AUTOSAR XML (schema 00047)
# (C) 2021 HYUNDAI AUTOEVER Corp.
# Confidential Proprietary Information. Distribution Limited.
# Do Not Copy Without Prior Permission
package /Svc_Dcm
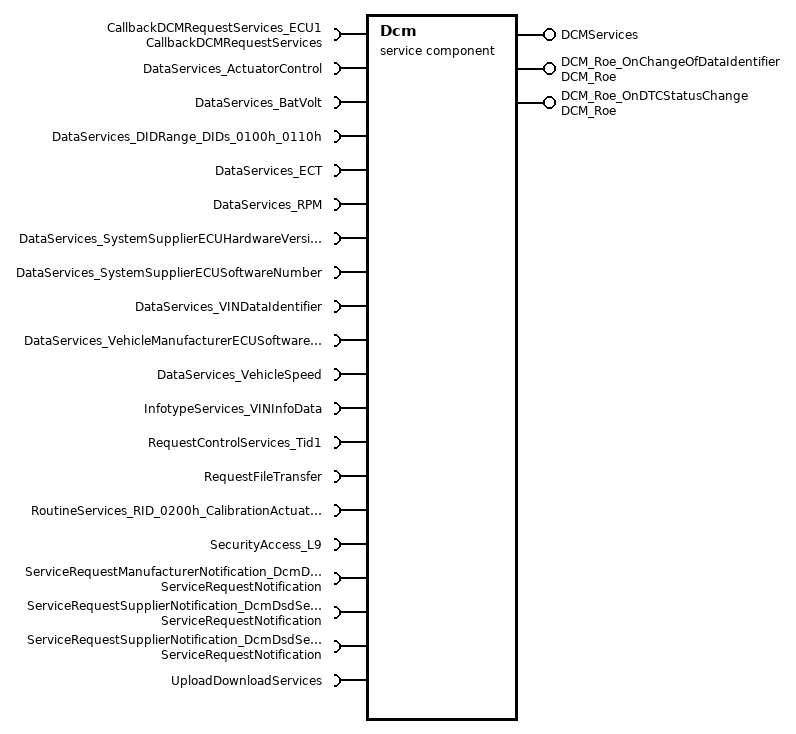
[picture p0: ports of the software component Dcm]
  service sw component type Dcm
    require port CallbackDCMRequestServices_ECU1: required-com-specs=[StartProtocol, StopProtocol], required-interface=CallbackDCMRequestServices
    provide port DCMServices: provided-interface=DCMServices
      provided-com-specs:
        operation=GetActiveProtocol, queue-length=1
        operation=GetSecurityLevel, queue-length=1
        operation=GetSesCtrlType, queue-length=1
        operation=ResetToDefaultSession, queue-length=1
        operation=SetActiveDiagnostic, queue-length=1
    provide port DCM_Roe_OnChangeOfDataIdentifier: server-com-spec{operation=TriggerOnEvent, queue-length=1}, provided-interface=DCM_Roe
    provide port DCM_Roe_OnDTCStatusChange: server-com-spec{operation=TriggerOnEvent, queue-length=1}, provided-interface=DCM_Roe
    19 x require port:
      DataServices_ActuatorControl: required-interface=DataServices_ActuatorControl
        required-com-specs:
          DataServices_ActuatorControl/ConditionCheckRead
          DataServices_ActuatorControl/ReadData
          DataServices_ActuatorControl/WriteData
          DataServices_ActuatorControl/FreezeCurrentState
          ResetToDefault
          DataServices_ActuatorControl/ReturnControlToECU
          DataServices_ActuatorControl/ShortTermAdjustment
      DataServices_BatVolt: required-com-specs=[DataServices_BatVolt/ConditionCheckRead, DataServices_BatVolt/ReadData, DataServices_BatVolt/WriteData], required-interface=DataServices_BatVolt
      DataServices_DIDRange_DIDs_0100h_0110h: required-com-specs=[IsDidAvailable, ReadDidData, ReadDidRangeDataLength, WriteDidData], required-interface=DataServices_DIDRange_DIDs_0100h_0110h
      DataServices_ECT: required-com-specs=[DataServices_ECT/ConditionCheckRead, DataServices_ECT/ReadData, DataServices_ECT/WriteData], required-interface=DataServices_ECT
      DataServices_RPM: required-interface=DataServices_RPM
        required-com-specs:
          DataServices_RPM/ConditionCheckRead
          DataServices_RPM/ReadData
          DataServices_RPM/WriteData
          DataServices_RPM/FreezeCurrentState
          DataServices_RPM/ReturnControlToECU
          DataServices_RPM/ShortTermAdjustment
      DataServices_SystemSupplierECUHardwareVersionNumber: required-interface=DataServices_SystemSupplierECUHardwareVersionNumber
        required-com-specs:
          DataServices_SystemSupplierECUHardwareVersionNumber/ConditionCheckRead
          DataServices_SystemSupplierECUHardwareVersionNumber/ReadData
      DataServices_SystemSupplierECUSoftwareNumber: required-interface=DataServices_SystemSupplierECUSoftwareNumber
        required-com-specs:
          DataServices_SystemSupplierECUSoftwareNumber/ConditionCheckRead
          DataServices_SystemSupplierECUSoftwareNumber/ReadData
      DataServices_VINDataIdentifier: required-interface=DataServices_VINDataIdentifier
        required-com-specs:
          DataServices_VINDataIdentifier/ConditionCheckRead
          DataServices_VINDataIdentifier/GetScalingInformation
          DataServices_VINDataIdentifier/ReadData
          DataServices_VINDataIdentifier/WriteData
      DataServices_VehicleManufacturerECUSoftwareVersionNumber: required-interface=DataServices_VehicleManufacturerECUSoftwareVersionNumber
        required-com-specs:
          DataServices_VehicleManufacturerECUSoftwareVersionNumber/ConditionCheckRead
          DataServices_VehicleManufacturerECUSoftwareVersionNumber/ReadData
      DataServices_VehicleSpeed: required-interface=DataServices_VehicleSpeed
        required-com-specs:
          DataServices_VehicleSpeed/ConditionCheckRead
          DataServices_VehicleSpeed/GetScalingInformation
          DataServices_VehicleSpeed/ReadData
      InfotypeServices_VINInfoData: client-com-spec=GetInfotypeValueData, required-interface=InfotypeServices_VINInfoData
      RequestControlServices_Tid1: client-com-spec=RequestControl, required-interface=RequestControlServices_Tid1
      RequestFileTransfer: required-interface=RequestFileTransfer
        required-com-specs:
          ProcessRequestAddFile
          ProcessRequestDeleteFile
          ProcessRequestReadDir
          ProcessRequestReadFile
          ProcessRequestReplaceFile
          ReadFileOrDir
          WriteFile
      RoutineServices_RID_0200h_CalibrationActuator: required-com-specs=[Stop, Start, RequestResults], required-interface=RoutineServices_RID_0200h_CalibrationActuator
      SecurityAccess_L9: required-com-specs=[CompareKey, GetSeed], required-interface=SecurityAccess_L9
      ServiceRequestManufacturerNotification_DcmDsdServiceRequestManufacturerNotification0: required-com-specs=[Confirmation, Indication], required-interface=ServiceRequestNotification
      ServiceRequestSupplierNotification_DcmDsdServiceRequestSupplierNotification0: required-com-specs=[Confirmation, Indication], required-interface=ServiceRequestNotification
      ServiceRequestSupplierNotification_DcmDsdServiceRequestSupplierNotification1: required-com-specs=[Confirmation, Indication], required-interface=ServiceRequestNotification
      UploadDownloadServices: required-interface=UploadDownloadServices
        required-com-specs:
          ProcessRequestDownload
          ProcessRequestUpload
          ProcessRequestTransferExit
          ProcessTransferDataRead
          ProcessTransferDataWrite
    behavior DcmInternalBehavior: handle-termination-and-restart=NO-SUPPORT, included-data-type-set=data-type=[Dcm_CertAuthorizationInfoType, Dcm_CertExpirationDateInfoType, Dcm_CertInfoType, Dcm_ConfirmationStatusType, Dcm_DataArrayTypeUint8_ActuatorControlType, Dcm_DataArrayTypeUint8_RPMType, Dcm_DataElement_ActuatorControlType, Dcm_DataElement_ActuatorControl_ArrayType, Dcm_DataElement_BatVoltType, Dcm_DataElement_BatVolt_ArrayType, Dcm_DataElement_ECTType, Dcm_DataElement_ECT_ArrayType, Dcm_DataElement_RPMType, Dcm_DataElement_RPM_ArrayType, Dcm_DataElement_SystemSupplierECUHardwareVersionNumberType, Dcm_DataElement_SystemSupplierECUHardwareVersionNumber_ArrayType, Dcm_DataElement_SystemSupplierECUSoftwareNumberType, Dcm_DataElement_SystemSupplierECUSoftwareNumber_ArrayType, Dcm_DataElement_VINDataIdentifierType, Dcm_DataElement_VINDataIdentifier_ArrayType, Dcm_DataElement_VehicleManufacturerECUSoftwareVersionNumberType, Dcm_DataElement_VehicleManufacturerECUSoftwareVersionNumber_ArrayType, Dcm_DataElement_VehicleSpeedType, Dcm_DataElement_VehicleSpeed_ArrayType, Dcm_DidSupportedType, Dcm_FileAndDirNameType, Dcm_IOOperationResponseType, Dcm_InfoTypeServicesArray_VINInfoDataType, Dcm_InputOutputControlParameterType, Dcm_KeyArray_L9Type, Dcm_NegativeResponseCodeType, Dcm_OpStatusType, Dcm_ProtocolType, Dcm_RangeArray_DIDs_0100h_0110hType, Dcm_RequestControlServicesInArray_Tid1Type, Dcm_RequestControlServicesOutArray_Tid1Type, Dcm_RequestDataArrayType, Dcm_RequestDataOut_RID_0200h_CalibrationActuator_RID_0200h_RequestOutSignalType, Dcm_RequestDataOut_RID_0200h_CalibrationActuator_RID_0200h_RequestOutSignal_PrimitiveType, Dcm_ResponseDataArrayType, Dcm_ScalingInfoArray_VINDataIdentifierType, Dcm_ScalingInfoArray_VehicleSpeedType, Dcm_SecLevelType, Dcm_SeedArray_L9Type, Dcm_SesCtrlType, Dcm_StartDataIn_RID_0200h_CalibrationActuator_RID_0200h_StartInSignalType, Dcm_StartDataIn_RID_0200h_CalibrationActuator_RID_0200h_StartInSignal_PrimitiveType, Dcm_StartDataOut_RID_0200h_CalibrationActuator_RID_0200h_StartOutSignalType, Dcm_StartDataOut_RID_0200h_CalibrationActuator_RID_0200h_StartOutSignal_PrimitiveType, Dcm_StopDataIn_RID_0200h_CalibrationActuator_RID_0200h_StopInSignalType, Dcm_StopDataIn_RID_0200h_CalibrationActuator_RID_0200h_StopInSignal_PrimitiveType, Dcm_StopDataOut_RID_0200h_CalibrationActuator_RID_0200h_StopOutSignalType, Dcm_StopDataOut_RID_0200h_CalibrationActuator_RID_0200h_StopOutSignal_PrimitiveType]
      7 x operation invoked event:
        IOE_DCM_Roe_OnChangeOfDataIdentifier_TriggerOnEvent: start-on-event=TriggerOnEvent, operation=DCM_Roe_OnChangeOfDataIdentifier.TriggerOnEvent
        IOE_DCM_Roe_OnDTCStatusChange_TriggerOnEvent: start-on-event=TriggerOnEvent, operation=DCM_Roe_OnDTCStatusChange.TriggerOnEvent
        OIE_DCMServices_GetActiveProtocol: start-on-event=GetActiveProtocol, operation=DCMServices.GetActiveProtocol
        OIE_DCMServices_GetSecurityLevel: start-on-event=GetSecurityLevel, operation=DCMServices.GetSecurityLevel
        OIE_DCMServices_GetSesCtrlType: start-on-event=GetSesCtrlType, operation=DCMServices.GetSesCtrlType
        OIE_DCMServices_ResetToDefaultSession: start-on-event=ResetToDefaultSession, operation=DCMServices.ResetToDefaultSession
        OIE_DCMServices_SetActiveDiagnostic: start-on-event=SetActiveDiagnostic, operation=DCMServices.SetActiveDiagnostic
      port-api-options:
        {enable-take-address=false, indirect-api=false, port-defined-argument-value{value=0x00, value-type=uint8}, port=DCM_Roe_OnDTCStatusChange}
        {enable-take-address=false, indirect-api=false, port-defined-argument-value{value=0x01, value-type=uint8}, port=DCM_Roe_OnChangeOfDataIdentifier}
      7 x runnable, all with can-be-invoked-concurrently=true:
        GetActiveProtocol: symbol=Dcm_GetActiveProtocol
        GetSecurityLevel: symbol=Dcm_GetSecurityLevel
        GetSesCtrlType: symbol=Dcm_GetSesCtrlType
        MainFunction: symbol=Dcm_MainFunction
          63 x sync call, all with timeout=0.0:
            SSCP_CallbackDCMRequestServices_ECU1_StartProtocol: operation=CallbackDCMRequestServices_ECU1.StartProtocol
            SSCP_CallbackDCMRequestServices_ECU1_StopProtocol: operation=CallbackDCMRequestServices_ECU1.StopProtocol
            SSCP_DataServices_ActuatorControl_ConditionCheckRead: operation=DataServices_ActuatorControl.ConditionCheckRead
            SSCP_DataServices_ActuatorControl_FreezeCurrentState: operation=DataServices_ActuatorControl.FreezeCurrentState
            SSCP_DataServices_ActuatorControl_ReadData: operation=DataServices_ActuatorControl.ReadData
            SSCP_DataServices_ActuatorControl_ResetToDefault: operation=DataServices_ActuatorControl.ResetToDefault
            SSCP_DataServices_ActuatorControl_ReturnControlToECU: operation=DataServices_ActuatorControl.ReturnControlToECU
            SSCP_DataServices_ActuatorControl_ShortTermAdjustment: operation=DataServices_ActuatorControl.ShortTermAdjustment
            SSCP_DataServices_ActuatorControl_WriteData: operation=DataServices_ActuatorControl.WriteData
            SSCP_DataServices_BatVolt_ConditionCheckRead: operation=DataServices_BatVolt.ConditionCheckRead
            SSCP_DataServices_BatVolt_ReadData: operation=DataServices_BatVolt.ReadData
            SSCP_DataServices_BatVolt_WriteData: operation=DataServices_BatVolt.WriteData
            SSCP_DataServices_DIDRange_DIDs_0100h_0110h_IsDidAvailable: operation=DataServices_DIDRange_DIDs_0100h_0110h.IsDidAvailable
            SSCP_DataServices_DIDRange_DIDs_0100h_0110h_ReadDidData: operation=DataServices_DIDRange_DIDs_0100h_0110h.ReadDidData
            SSCP_DataServices_DIDRange_DIDs_0100h_0110h_ReadDidRangeDataLength: operation=DataServices_DIDRange_DIDs_0100h_0110h.ReadDidRangeDataLength
            SSCP_DataServices_DIDRange_DIDs_0100h_0110h_WriteDidData: operation=DataServices_DIDRange_DIDs_0100h_0110h.WriteDidData
            SSCP_DataServices_ECT_ConditionCheckRead: operation=DataServices_ECT.ConditionCheckRead
            SSCP_DataServices_ECT_ReadData: operation=DataServices_ECT.ReadData
            SSCP_DataServices_ECT_WriteData: operation=DataServices_ECT.WriteData
            SSCP_DataServices_RPM_ConditionCheckRead: operation=DataServices_RPM.ConditionCheckRead
            SSCP_DataServices_RPM_FreezeCurrentState: operation=DataServices_RPM.FreezeCurrentState
            SSCP_DataServices_RPM_ReadData: operation=DataServices_RPM.ReadData
            SSCP_DataServices_RPM_ReturnControlToECU: operation=DataServices_RPM.ReturnControlToECU
            SSCP_DataServices_RPM_ShortTermAdjustment: operation=DataServices_RPM.ShortTermAdjustment
            SSCP_DataServices_RPM_WriteData: operation=DataServices_RPM.WriteData
            SSCP_DataServices_SystemSupplierECUHardwareVersionNumber_ConditionCheckRead: operation=DataServices_SystemSupplierECUHardwareVersionNumber.ConditionCheckRead
            SSCP_DataServices_SystemSupplierECUHardwareVersionNumber_ReadData: operation=DataServices_SystemSupplierECUHardwareVersionNumber.ReadData
            SSCP_DataServices_SystemSupplierECUSoftwareNumber_ConditionCheckRead: operation=DataServices_SystemSupplierECUSoftwareNumber.ConditionCheckRead
            SSCP_DataServices_SystemSupplierECUSoftwareNumber_ReadData: operation=DataServices_SystemSupplierECUSoftwareNumber.ReadData
            SSCP_DataServices_VINDataIdentifier_ConditionCheckRead: operation=DataServices_VINDataIdentifier.ConditionCheckRead
            SSCP_DataServices_VINDataIdentifier_GetScalingInformation: operation=DataServices_VINDataIdentifier.GetScalingInformation
            SSCP_DataServices_VINDataIdentifier_ReadData: operation=DataServices_VINDataIdentifier.ReadData
            SSCP_DataServices_VINDataIdentifier_WriteData: operation=DataServices_VINDataIdentifier.WriteData
            SSCP_DataServices_VehicleManufacturerECUSoftwareVersionNumber_ConditionCheckRead: operation=DataServices_VehicleManufacturerECUSoftwareVersionNumber.ConditionCheckRead
            SSCP_DataServices_VehicleManufacturerECUSoftwareVersionNumber_ReadData: operation=DataServices_VehicleManufacturerECUSoftwareVersionNumber.ReadData
            SSCP_DataServices_VehicleSpeed_ConditionCheckRead: operation=DataServices_VehicleSpeed.ConditionCheckRead
            SSCP_DataServices_VehicleSpeed_GetScalingInformation: operation=DataServices_VehicleSpeed.GetScalingInformation
            SSCP_DataServices_VehicleSpeed_ReadData: operation=DataServices_VehicleSpeed.ReadData
            SSCP_InfotypeServices_VINInfoData_GetInfotypeValueData: operation=InfotypeServices_VINInfoData.GetInfotypeValueData
            SSCP_RequestControlServices_Tid1_RequestControl: operation=RequestControlServices_Tid1.RequestControl
            SSCP_RequestFileTransfer_ProcessRequestAddFile: operation=RequestFileTransfer.ProcessRequestAddFile
            SSCP_RequestFileTransfer_ProcessRequestDeleteFile: operation=RequestFileTransfer.ProcessRequestDeleteFile
            SSCP_RequestFileTransfer_ProcessRequestReadDir: operation=RequestFileTransfer.ProcessRequestReadDir
            SSCP_RequestFileTransfer_ProcessRequestReadFile: operation=RequestFileTransfer.ProcessRequestReadFile
            SSCP_RequestFileTransfer_ProcessRequestReplaceFile: operation=RequestFileTransfer.ProcessRequestReplaceFile
            SSCP_RequestFileTransfer_ReadFileOrDir: operation=RequestFileTransfer.ReadFileOrDir
            SSCP_RequestFileTransfer_WriteFile: operation=RequestFileTransfer.WriteFile
            SSCP_RoutineServices_RID_0200h_CalibrationActuator_RequestResults: operation=RoutineServices_RID_0200h_CalibrationActuator.RequestResults
            SSCP_RoutineServices_RID_0200h_CalibrationActuator_Start: operation=RoutineServices_RID_0200h_CalibrationActuator.Start
            SSCP_RoutineServices_RID_0200h_CalibrationActuator_Stop: operation=RoutineServices_RID_0200h_CalibrationActuator.Stop
            SSCP_SecurityAccess_L9_CompareKey: operation=SecurityAccess_L9.CompareKey
            SSCP_SecurityAccess_L9_GetSeed: operation=SecurityAccess_L9.GetSeed
            SSCP_ServiceRequestManufacturerNotification_DcmDsdServiceRequestManufacturerNotification0_Confirmation: operation=ServiceRequestManufacturerNotification_DcmDsdServiceRequestManufacturerNotification0.Confirmation
            SSCP_ServiceRequestManufacturerNotification_DcmDsdServiceRequestManufacturerNotification0_Indication: operation=ServiceRequestManufacturerNotification_DcmDsdServiceRequestManufacturerNotification0.Indication
            SSCP_ServiceRequestSupplierNotification_DcmDsdServiceRequestSupplierNotification0_Confirmation: operation=ServiceRequestSupplierNotification_DcmDsdServiceRequestSupplierNotification0.Confirmation
            SSCP_ServiceRequestSupplierNotification_DcmDsdServiceRequestSupplierNotification0_Indication: operation=ServiceRequestSupplierNotification_DcmDsdServiceRequestSupplierNotification0.Indication
            SSCP_ServiceRequestSupplierNotification_DcmDsdServiceRequestSupplierNotification1_Confirmation: operation=ServiceRequestSupplierNotification_DcmDsdServiceRequestSupplierNotification1.Confirmation
            SSCP_ServiceRequestSupplierNotification_DcmDsdServiceRequestSupplierNotification1_Indication: operation=ServiceRequestSupplierNotification_DcmDsdServiceRequestSupplierNotification1.Indication
            SSCP_UploadDownloadServices_ProcessRequestDownload: operation=UploadDownloadServices.ProcessRequestDownload
            SSCP_UploadDownloadServices_ProcessRequestTransferExit: operation=UploadDownloadServices.ProcessRequestTransferExit
            SSCP_UploadDownloadServices_ProcessRequestUpload: operation=UploadDownloadServices.ProcessRequestUpload
            SSCP_UploadDownloadServices_ProcessTransferDataRead: operation=UploadDownloadServices.ProcessTransferDataRead
            SSCP_UploadDownloadServices_ProcessTransferDataWrite: operation=UploadDownloadServices.ProcessTransferDataWrite
        ResetToDefaultSession: symbol=Dcm_ResetToDefaultSession
        SetActiveDiagnostic: symbol=Dcm_SetActiveDiagnostic
        TriggerOnEvent: symbol=Dcm_Runnable_TriggerOnEvent
  swc implementation Dcm_SwcImplementation: programming-language=C, sw-version=1.0.0, swc-bsw-mapping=SwcBswMapping_Dcm, vendor-id=76, behavior=DcmInternalBehavior
    code-descriptors:
      code CodeDescriptor: artifact-descriptors=autosar-engineering-object={short-label=Dcm_LibObjects, category=SWLIB, domain=AUTOSAR_DCM}
    resource consumption ResourceConsumption
  swc bsw mapping SwcBswMapping_Dcm: bsw-behavior=BswInternalBehavior_Dcm, swc-bsw-runnable-mapping{bsw-entity=BswSE_Dcm_MainFunction, swc-runnable=MainFunction}, swc-behavior=DcmInternalBehavior
package /Svc_Dcm/ClientServerInterfaces
  20 x client server interface, all with is-service=true:
    CallbackDCMRequestServices
      operation StartProtocol: possible-error=[CallbackDCMRequestServices/E_NOT_OK, CallbackDCMRequestServices/E_OK, E_PROTOCOL_NOT_ALLOWED]
        arg ProtocolType: type=Dcm_ProtocolType, direction=IN
        arg TesterSourceAddress: type=uint16, direction=IN
        arg ConnectionId: type=uint16, direction=IN
      operation StopProtocol: possible-error=[CallbackDCMRequestServices/E_NOT_OK, CallbackDCMRequestServices/E_OK]
        arg ProtocolType: type=Dcm_ProtocolType, direction=IN
        arg TesterSourceAddress: type=uint16, direction=IN
        arg ConnectionId: type=uint16, direction=IN
      error E_NOT_OK: error-code=1
      error E_OK: error-code=0
      error E_PROTOCOL_NOT_ALLOWED: error-code=5
    DCMServices
      5 x operation:
        GetActiveProtocol: possible-error=DCMServices/E_OK
          arg ActiveProtocolType: type=Dcm_ProtocolType, direction=OUT
          arg ConnectionId: type=uint16, direction=OUT
          arg TesterSourceAddress: type=uint16, direction=OUT
        GetSecurityLevel: possible-error=[DCMServices/E_NOT_OK, DCMServices/E_OK]
          arg SecLevel: type=Dcm_SecLevelType, direction=OUT
        GetSesCtrlType: possible-error=[DCMServices/E_NOT_OK, DCMServices/E_OK]
          arg SesCtrlType: type=Dcm_SesCtrlType, direction=OUT
        ResetToDefaultSession: possible-error=[DCMServices/E_NOT_OK, DCMServices/E_OK]
        SetActiveDiagnostic: possible-error=DCMServices/E_OK
          arg ArgumentDataPrototype0: type=boolean, direction=IN
      error E_NOT_OK: error-code=1
      error E_OK: error-code=0
    DCM_Roe
      operation TriggerOnEvent: possible-error=[DCM_Roe/E_NOT_OK, DCM_Roe/E_OK]
      error E_NOT_OK: error-code=1
      error E_OK: error-code=0
    DataServices_ActuatorControl
      7 x operation, all with possible-error=[DataServices_ActuatorControl/E_NOT_OK, DataServices_ActuatorControl/E_OK]:
        ConditionCheckRead
          arg ErrorCode: type=Dcm_NegativeResponseCodeType, direction=OUT
        FreezeCurrentState
          arg ErrorCode: type=Dcm_NegativeResponseCodeType, direction=OUT
        ReadData
          arg Data: type=Dcm_DataElement_ActuatorControlType, direction=OUT
        ResetToDefault
          arg ErrorCode: type=Dcm_NegativeResponseCodeType, direction=OUT
        ReturnControlToECU
          arg ErrorCode: type=Dcm_NegativeResponseCodeType, direction=OUT
        ShortTermAdjustment
          arg ControlStateInfo: type=Dcm_DataArrayTypeUint8_ActuatorControlType, direction=IN
          arg ErrorCode: type=Dcm_NegativeResponseCodeType, direction=OUT
        WriteData
          arg Data: type=Dcm_DataElement_ActuatorControlType, direction=IN
          arg ErrorCode: type=Dcm_NegativeResponseCodeType, direction=OUT
      error DCM_E_PENDING: error-code=10
      error E_NOT_OK: error-code=1
      error E_OK: error-code=0
    DataServices_BatVolt
      operation ConditionCheckRead: possible-error=[DataServices_BatVolt/E_NOT_OK, DataServices_BatVolt/E_OK]
        arg ErrorCode: type=Dcm_NegativeResponseCodeType, direction=OUT
      operation ReadData: possible-error=[DataServices_BatVolt/E_NOT_OK, DataServices_BatVolt/E_OK]
        arg Data: type=Dcm_DataElement_BatVoltType, direction=OUT
      operation WriteData: possible-error=[DataServices_BatVolt/E_NOT_OK, DataServices_BatVolt/E_OK]
        arg Data: type=Dcm_DataElement_BatVoltType, direction=IN
        arg ErrorCode: type=Dcm_NegativeResponseCodeType, direction=OUT
      error DCM_E_PENDING: error-code=10
      error E_NOT_OK: error-code=1
      error E_OK: error-code=0
    DataServices_DIDRange_DIDs_0100h_0110h
      4 x operation:
        IsDidAvailable: possible-error=[DataServices_DIDRange_DIDs_0100h_0110h/DCM_E_PENDING, DataServices_DIDRange_DIDs_0100h_0110h/E_OK]
          arg DID: type=uint16, direction=IN
          arg OpStatus: type=Dcm_OpStatusType, direction=IN
          arg Supported: type=Dcm_DidSupportedType, direction=OUT
        ReadDidData: possible-error=[DataServices_DIDRange_DIDs_0100h_0110h/DCM_E_PENDING, DataServices_DIDRange_DIDs_0100h_0110h/E_NOT_OK, DataServices_DIDRange_DIDs_0100h_0110h/E_OK]
          5 x arg:
            DID: type=uint16, direction=IN
            Data: type=Dcm_RangeArray_DIDs_0100h_0110hType, direction=OUT
            OpStatus: type=Dcm_OpStatusType, direction=IN
            DataLength: type=uint16, direction=OUT
            ErrorCode: type=Dcm_NegativeResponseCodeType, direction=OUT
        ReadDidRangeDataLength: possible-error=[DataServices_DIDRange_DIDs_0100h_0110h/DCM_E_PENDING, DataServices_DIDRange_DIDs_0100h_0110h/E_NOT_OK, DataServices_DIDRange_DIDs_0100h_0110h/E_OK]
          arg DID: type=uint16, direction=IN
          arg OpStatus: type=Dcm_OpStatusType, direction=IN
          arg DataLength: type=uint16, direction=OUT
        WriteDidData: possible-error=[DataServices_DIDRange_DIDs_0100h_0110h/DCM_E_PENDING, DataServices_DIDRange_DIDs_0100h_0110h/E_NOT_OK, DataServices_DIDRange_DIDs_0100h_0110h/E_OK]
          5 x arg:
            DID: type=uint16, direction=IN
            Data: type=Dcm_RangeArray_DIDs_0100h_0110hType, direction=IN
            OpStatus: type=Dcm_OpStatusType, direction=IN
            DataLength: type=uint16, direction=IN
            ErrorCode: type=Dcm_NegativeResponseCodeType, direction=OUT
      error DCM_E_PENDING: error-code=10
      error E_NOT_OK: error-code=1
      error E_OK: error-code=0
    DataServices_ECT
      operation ConditionCheckRead: possible-error=[DataServices_ECT/E_NOT_OK, DataServices_ECT/E_OK]
        arg ErrorCode: type=Dcm_NegativeResponseCodeType, direction=OUT
      operation ReadData: possible-error=[DataServices_ECT/E_NOT_OK, DataServices_ECT/E_OK]
        arg Data: type=Dcm_DataElement_ECTType, direction=OUT
      operation WriteData: possible-error=[DataServices_ECT/E_NOT_OK, DataServices_ECT/E_OK]
        arg Data: type=Dcm_DataElement_ECTType, direction=IN
        arg ErrorCode: type=Dcm_NegativeResponseCodeType, direction=OUT
      error DCM_E_PENDING: error-code=10
      error E_NOT_OK: error-code=1
      error E_OK: error-code=0
    DataServices_RPM
      6 x operation, all with possible-error=[DataServices_RPM/E_NOT_OK, DataServices_RPM/E_OK]:
        ConditionCheckRead
          arg ErrorCode: type=Dcm_NegativeResponseCodeType, direction=OUT
        FreezeCurrentState
          arg ErrorCode: type=Dcm_NegativeResponseCodeType, direction=OUT
        ReadData
          arg Data: type=Dcm_DataElement_RPMType, direction=OUT
        ReturnControlToECU
          arg ErrorCode: type=Dcm_NegativeResponseCodeType, direction=OUT
        ShortTermAdjustment
          arg ControlStateInfo: type=Dcm_DataArrayTypeUint8_RPMType, direction=IN
          arg ErrorCode: type=Dcm_NegativeResponseCodeType, direction=OUT
        WriteData
          arg Data: type=Dcm_DataElement_RPMType, direction=IN
          arg ErrorCode: type=Dcm_NegativeResponseCodeType, direction=OUT
      error DCM_E_PENDING: error-code=10
      error E_NOT_OK: error-code=1
      error E_OK: error-code=0
    DataServices_SystemSupplierECUHardwareVersionNumber
      operation ConditionCheckRead: possible-error=[DataServices_SystemSupplierECUHardwareVersionNumber/E_NOT_OK, DataServices_SystemSupplierECUHardwareVersionNumber/E_OK]
        arg ErrorCode: type=Dcm_NegativeResponseCodeType, direction=OUT
      operation ReadData: possible-error=[DataServices_SystemSupplierECUHardwareVersionNumber/E_NOT_OK, DataServices_SystemSupplierECUHardwareVersionNumber/E_OK]
        arg Data: type=Dcm_DataElement_SystemSupplierECUHardwareVersionNumberType, direction=OUT
      error DCM_E_PENDING: error-code=10
      error E_NOT_OK: error-code=1
      error E_OK: error-code=0
    DataServices_SystemSupplierECUSoftwareNumber
      operation ConditionCheckRead: possible-error=[DataServices_SystemSupplierECUSoftwareNumber/E_NOT_OK, DataServices_SystemSupplierECUSoftwareNumber/E_OK]
        arg ErrorCode: type=Dcm_NegativeResponseCodeType, direction=OUT
      operation ReadData: possible-error=[DataServices_SystemSupplierECUSoftwareNumber/E_NOT_OK, DataServices_SystemSupplierECUSoftwareNumber/E_OK]
        arg Data: type=Dcm_DataElement_SystemSupplierECUSoftwareNumberType, direction=OUT
      error DCM_E_PENDING: error-code=10
      error E_NOT_OK: error-code=1
      error E_OK: error-code=0
    DataServices_VINDataIdentifier
      4 x operation, all with possible-error=[DataServices_VINDataIdentifier/E_NOT_OK, DataServices_VINDataIdentifier/E_OK]:
        ConditionCheckRead
          arg ErrorCode: type=Dcm_NegativeResponseCodeType, direction=OUT
        GetScalingInformation
          arg ScalingInfo: type=Dcm_ScalingInfoArray_VINDataIdentifierType, direction=OUT
          arg ErrorCode: type=Dcm_NegativeResponseCodeType, direction=OUT
        ReadData
          arg Data: type=Dcm_DataElement_VINDataIdentifierType, direction=OUT
        WriteData
          arg Data: type=Dcm_DataElement_VINDataIdentifierType, direction=IN
          arg ErrorCode: type=Dcm_NegativeResponseCodeType, direction=OUT
      error DCM_E_PENDING: error-code=10
      error E_NOT_OK: error-code=1
      error E_OK: error-code=0
    DataServices_VehicleManufacturerECUSoftwareVersionNumber
      operation ConditionCheckRead: possible-error=[DataServices_VehicleManufacturerECUSoftwareVersionNumber/E_NOT_OK, DataServices_VehicleManufacturerECUSoftwareVersionNumber/E_OK]
        arg ErrorCode: type=Dcm_NegativeResponseCodeType, direction=OUT
      operation ReadData: possible-error=[DataServices_VehicleManufacturerECUSoftwareVersionNumber/E_NOT_OK, DataServices_VehicleManufacturerECUSoftwareVersionNumber/E_OK]
        arg Data: type=Dcm_DataElement_VehicleManufacturerECUSoftwareVersionNumberType, direction=OUT
      error DCM_E_PENDING: error-code=10
      error E_NOT_OK: error-code=1
      error E_OK: error-code=0
    DataServices_VehicleSpeed
      operation ConditionCheckRead: possible-error=[DataServices_VehicleSpeed/E_NOT_OK, DataServices_VehicleSpeed/E_OK]
        arg ErrorCode: type=Dcm_NegativeResponseCodeType, direction=OUT
      operation GetScalingInformation: possible-error=[DataServices_VehicleSpeed/E_NOT_OK, DataServices_VehicleSpeed/E_OK]
        arg ScalingInfo: type=Dcm_ScalingInfoArray_VehicleSpeedType, direction=OUT
        arg ErrorCode: type=Dcm_NegativeResponseCodeType, direction=OUT
      operation ReadData: possible-error=[DataServices_VehicleSpeed/E_NOT_OK, DataServices_VehicleSpeed/E_OK]
        arg Data: type=Dcm_DataElement_VehicleSpeedType, direction=OUT
      error DCM_E_PENDING: error-code=10
      error E_NOT_OK: error-code=1
      error E_OK: error-code=0
    InfotypeServices_VINInfoData
      operation GetInfotypeValueData: possible-error=[InfotypeServices_VINInfoData/DCM_E_PENDING, InfotypeServices_VINInfoData/E_NOT_OK, InfotypeServices_VINInfoData/E_OK]
        arg OpStatus: type=Dcm_OpStatusType, direction=IN
        arg DataValueBuffer: type=Dcm_InfoTypeServicesArray_VINInfoDataType, direction=OUT
        arg DataValueBufferSize: type=uint8, direction=INOUT
      error DCM_E_PENDING: error-code=10
      error E_NOT_OK: error-code=1
      error E_OK: error-code=0
    RequestControlServices_Tid1
      operation RequestControl: possible-error=[RequestControlServices_Tid1/E_NOT_OK, RequestControlServices_Tid1/E_OK]
        arg OutBuffer: type=Dcm_RequestControlServicesOutArray_Tid1Type, direction=OUT
        arg InBuffer: type=Dcm_RequestControlServicesInArray_Tid1Type, direction=IN
      error E_NOT_OK: error-code=1
      error E_OK: error-code=0
    RequestFileTransfer
      7 x operation, all with possible-error=[RequestFileTransfer/DCM_E_FORCE_RCRRP, RequestFileTransfer/DCM_E_PENDING, RequestFileTransfer/E_NOT_OK, RequestFileTransfer/E_OK]:
        ProcessRequestAddFile
          8 x arg:
            OpStatus: type=Dcm_OpStatusType, direction=IN
            filePathAndNameLength: type=uint16, direction=IN
            filePathAndName: type=Dcm_FileAndDirNameType, direction=IN
            dataFormatIdentifier: type=uint8, direction=IN
            fileSizeUncompressed: type=uint64, direction=IN
            fileSizeCompressed: type=uint64, direction=IN
            maxNumberOfBlockLength: type=uint64, direction=OUT
            ErrorCode: type=Dcm_NegativeResponseCodeType, direction=OUT
        ProcessRequestDeleteFile
          4 x arg:
            OpStatus: type=Dcm_OpStatusType, direction=IN
            filePathAndNameLength: type=uint16, direction=IN
            filePathAndName: type=Dcm_FileAndDirNameType, direction=IN
            ErrorCode: type=Dcm_NegativeResponseCodeType, direction=OUT
        ProcessRequestReadDir
          6 x arg:
            OpStatus: type=Dcm_OpStatusType, direction=IN
            filePathAndNameLength: type=uint16, direction=IN
            filePathAndName: type=Dcm_FileAndDirNameType, direction=IN
            dirInfoLength: type=uint64, direction=OUT
            maxNumberOfBlockLength: type=uint64, direction=OUT
            ErrorCode: type=Dcm_NegativeResponseCodeType, direction=OUT
        ProcessRequestReadFile
          8 x arg:
            OpStatus: type=Dcm_OpStatusType, direction=IN
            filePathAndNameLength: type=uint16, direction=IN
            filePathAndName: type=Dcm_FileAndDirNameType, direction=IN
            dataFormatIdentifier: type=uint8, direction=IN
            fileSizeUncompressed: type=uint64, direction=OUT
            fileSizeCompressed: type=uint64, direction=OUT
            maxNumberOfBlockLength: type=uint64, direction=OUT
            ErrorCode: type=Dcm_NegativeResponseCodeType, direction=OUT
        ProcessRequestReplaceFile
          8 x arg:
            OpStatus: type=Dcm_OpStatusType, direction=IN
            filePathAndNameLength: type=uint16, direction=IN
            filePathAndName: type=Dcm_FileAndDirNameType, direction=IN
            dataFormatIdentifier: type=uint8, direction=IN
            fileSizeUncompressed: type=uint64, direction=IN
            fileSizeCompressed: type=uint64, direction=IN
            maxNumberOfBlockLength: type=uint64, direction=OUT
            ErrorCode: type=Dcm_NegativeResponseCodeType, direction=OUT
        ReadFileOrDir
          4 x arg:
            OpStatus: type=Dcm_OpStatusType, direction=IN
            DataLength: type=uint64, direction=INOUT
            Data: type=Dcm_ResponseDataArrayType, direction=OUT
            ErrorCode: type=Dcm_NegativeResponseCodeType, direction=OUT
        WriteFile
          4 x arg:
            OpStatus: type=Dcm_OpStatusType, direction=IN
            DataLength: type=uint64, direction=IN
            Data: type=Dcm_ResponseDataArrayType, direction=IN
            ErrorCode: type=Dcm_NegativeResponseCodeType, direction=OUT
      4 x error:
        DCM_E_FORCE_RCRRP: error-code=12
        DCM_E_PENDING: error-code=10
        E_NOT_OK: error-code=1
        E_OK: error-code=0
    RoutineServices_RID_0200h_CalibrationActuator
      operation RequestResults: possible-error=[RoutineServices_RID_0200h_CalibrationActuator/DCM_E_FORCE_RCRRP, RoutineServices_RID_0200h_CalibrationActuator/DCM_E_PENDING, RoutineServices_RID_0200h_CalibrationActuator/E_NOT_OK, RoutineServices_RID_0200h_CalibrationActuator/E_OK]
        arg OpStatus: type=Dcm_OpStatusType, direction=IN
        arg DataOut_RID_0200h_RequestOutSignal: type=Dcm_RequestDataOut_RID_0200h_CalibrationActuator_RID_0200h_RequestOutSignalType, direction=OUT
        arg ErrorCode: type=Dcm_NegativeResponseCodeType, direction=OUT
      operation Start: possible-error=[RoutineServices_RID_0200h_CalibrationActuator/DCM_E_FORCE_RCRRP, RoutineServices_RID_0200h_CalibrationActuator/DCM_E_PENDING, RoutineServices_RID_0200h_CalibrationActuator/E_NOT_OK, RoutineServices_RID_0200h_CalibrationActuator/E_OK]
        4 x arg:
          DataIn_RID_0200h_StartInSignal: type=Dcm_StartDataIn_RID_0200h_CalibrationActuator_RID_0200h_StartInSignalType, direction=IN
          OpStatus: type=Dcm_OpStatusType, direction=IN
          DataOut_RID_0200h_StartOutSignal: type=Dcm_StartDataOut_RID_0200h_CalibrationActuator_RID_0200h_StartOutSignalType, direction=OUT
          ErrorCode: type=Dcm_NegativeResponseCodeType, direction=OUT
      operation Stop: possible-error=[RoutineServices_RID_0200h_CalibrationActuator/DCM_E_FORCE_RCRRP, RoutineServices_RID_0200h_CalibrationActuator/DCM_E_PENDING, RoutineServices_RID_0200h_CalibrationActuator/E_NOT_OK, RoutineServices_RID_0200h_CalibrationActuator/E_OK]
        4 x arg:
          DataIn_RID_0200h_StopInSignal: type=Dcm_StopDataIn_RID_0200h_CalibrationActuator_RID_0200h_StopInSignalType, direction=IN
          OpStatus: type=Dcm_OpStatusType, direction=IN
          DataOut_RID_0200h_StopOutSignal: type=Dcm_StopDataOut_RID_0200h_CalibrationActuator_RID_0200h_StopOutSignalType, direction=OUT
          ErrorCode: type=Dcm_NegativeResponseCodeType, direction=OUT
      4 x error:
        DCM_E_FORCE_RCRRP: error-code=12
        DCM_E_PENDING: error-code=10
        E_NOT_OK: error-code=1
        E_OK: error-code=0
    SecurityAccess_L9
      operation CompareKey: possible-error=[DCM_E_COMPARE_KEY_FAILED, SecurityAccess_L9/DCM_E_PENDING, SecurityAccess_L9/E_NOT_OK, SecurityAccess_L9/E_OK]
        arg Key: type=Dcm_KeyArray_L9Type, direction=IN
        arg OpStatus: type=Dcm_OpStatusType, direction=IN
        arg ErrorCode: type=Dcm_NegativeResponseCodeType, direction=OUT
      operation GetSeed: possible-error=[SecurityAccess_L9/DCM_E_PENDING, SecurityAccess_L9/E_NOT_OK, SecurityAccess_L9/E_OK]
        arg OpStatus: type=Dcm_OpStatusType, direction=IN
        arg Seed: type=Dcm_SeedArray_L9Type, direction=OUT
        arg ErrorCode: type=Dcm_NegativeResponseCodeType, direction=OUT
      4 x error:
        DCM_E_COMPARE_KEY_FAILED: error-code=11
        DCM_E_PENDING: error-code=10
        E_NOT_OK: error-code=1
        E_OK: error-code=0
    ServiceRequestNotification
      operation Confirmation: possible-error=[ServiceRequestNotification/E_NOT_OK, ServiceRequestNotification/E_OK]
        6 x arg, all with direction=IN:
          SID: type=uint8
          ReqType: type=uint8
          ConnectionId: type=uint16
          ConfirmationStatus: type=Dcm_ConfirmationStatusType
          ProtocolType: type=Dcm_ProtocolType
          TesterSourceAddress: type=uint16
      operation Indication: possible-error=[ServiceRequestNotification/E_NOT_OK, ServiceRequestNotification/E_OK, E_REQUEST_NOT_ACCEPTED]
        8 x arg:
          SID: type=uint8, direction=IN
          RequestData: type=Dcm_RequestDataArrayType, direction=IN
          DataSize: type=uint16, direction=IN
          ReqType: type=uint8, direction=IN
          ConnectionId: type=uint16, direction=IN
          ErrorCode: type=Dcm_NegativeResponseCodeType, direction=OUT
          ProtocolType: type=Dcm_ProtocolType, direction=IN
          TesterSourceAddress: type=uint16, direction=IN
      error E_NOT_OK: error-code=1
      error E_OK: error-code=0
      error E_REQUEST_NOT_ACCEPTED: error-code=8
    UploadDownloadServices
      5 x operation:
        ProcessRequestDownload: possible-error=[UploadDownloadServices/DCM_E_PENDING, UploadDownloadServices/E_NOT_OK, UploadDownloadServices/E_OK]
          7 x arg:
            OpStatus: type=Dcm_OpStatusType, direction=IN
            DataFormatIdentifier: type=uint8, direction=IN
            MemoryIdentifier: type=uint8, direction=IN
            MemoryAddress: type=uint32, direction=IN
            MemorySize: type=uint32, direction=IN
            BlockLength: type=uint32, direction=INOUT
            ErrorCode: type=Dcm_NegativeResponseCodeType, direction=OUT
        ProcessRequestTransferExit: possible-error=[UploadDownloadServices/DCM_E_PENDING, UploadDownloadServices/E_NOT_OK, UploadDownloadServices/E_OK]
          arg OpStatus: type=Dcm_OpStatusType, direction=IN
          arg ErrorCode: type=Dcm_NegativeResponseCodeType, direction=OUT
        ProcessRequestUpload: possible-error=[UploadDownloadServices/DCM_E_PENDING, UploadDownloadServices/E_NOT_OK, UploadDownloadServices/E_OK]
          7 x arg:
            OpStatus: type=Dcm_OpStatusType, direction=IN
            DataFormatIdentifier: type=uint8, direction=IN
            MemoryIdentifier: type=uint8, direction=IN
            MemoryAddress: type=uint32, direction=IN
            MemorySize: type=uint32, direction=IN
            BlockLength: type=uint32, direction=INOUT
            ErrorCode: type=Dcm_NegativeResponseCodeType, direction=OUT
        ProcessTransferDataRead: possible-error=[UploadDownloadServices/DCM_E_FORCE_RCRRP, UploadDownloadServices/DCM_E_PENDING, UploadDownloadServices/E_NOT_OK, UploadDownloadServices/E_OK]
          6 x arg:
            OpStatus: type=Dcm_OpStatusType, direction=IN
            MemoryIdentifier: type=uint8, direction=IN
            MemoryAddress: type=uint32, direction=IN
            MemorySize: type=uint32, direction=IN
            MemoryData: type=Dcm_RequestDataArrayType, direction=OUT
            ErrorCode: type=Dcm_NegativeResponseCodeType, direction=OUT
        ProcessTransferDataWrite: possible-error=[UploadDownloadServices/DCM_E_FORCE_RCRRP, UploadDownloadServices/DCM_E_PENDING, UploadDownloadServices/E_NOT_OK, UploadDownloadServices/E_OK]
          6 x arg:
            OpStatus: type=Dcm_OpStatusType, direction=IN
            MemoryIdentifier: type=uint8, direction=IN
            MemoryAddress: type=uint32, direction=IN
            MemorySize: type=uint32, direction=IN
            MemoryData: type=Dcm_RequestDataArrayType, direction=IN
            ErrorCode: type=Dcm_NegativeResponseCodeType, direction=OUT
      4 x error:
        DCM_E_FORCE_RCRRP: error-code=12
        DCM_E_PENDING: error-code=10
        E_NOT_OK: error-code=1
        E_OK: error-code=0
package /Svc_Dcm/ImplementationDataTypes
  53 x impl type:
    Dcm_CertAuthorizationInfoType: category=ARRAY
      element authorization: array-size=4, array-size-semantics=FIXED-SIZE, implementation-data-type=uint8
    Dcm_CertExpirationDateInfoType: category=ARRAY
      element expirationDate: array-size=3, array-size-semantics=FIXED-SIZE, implementation-data-type=uint8
    Dcm_CertInfoType: category=STRUCTURE
      element authorization: implementation-data-type=Dcm_CertAuthorizationInfoType
      element expirationDate: implementation-data-type=Dcm_CertExpirationDateInfoType
    Dcm_ConfirmationStatusType: compu {0=DCM_RES_POS_OK, 1=DCM_RES_POS_NOT_OK, 2=DCM_RES_NEG_OK, 3=DCM_RES_NEG_NOT_OK}, range raw 0..3, implementation-data-type=uint8
    Dcm_DataArrayTypeUint8_ActuatorControlType: category=ARRAY
      element DataArrayUint8_ActuatorControl: array-size=1, array-size-semantics=FIXED-SIZE, implementation-data-type=uint8
    Dcm_DataArrayTypeUint8_RPMType: category=ARRAY
      element DataArrayUint8_RPM: array-size=2, array-size-semantics=FIXED-SIZE, implementation-data-type=uint8
    Dcm_DataElement_ActuatorControlType: implementation-data-type=Dcm_DataElement_ActuatorControl_ArrayType
    Dcm_DataElement_ActuatorControl_ArrayType: category=ARRAY
      element DataElement_ActuatorControl_Array: array-size=1, array-size-semantics=FIXED-SIZE, implementation-data-type=uint8
    Dcm_DataElement_BatVoltType: implementation-data-type=Dcm_DataElement_BatVolt_ArrayType
    Dcm_DataElement_BatVolt_ArrayType: category=ARRAY
      element DataElement_BatVolt_Array: array-size=1, array-size-semantics=FIXED-SIZE, implementation-data-type=uint8
    Dcm_DataElement_ECTType: implementation-data-type=Dcm_DataElement_ECT_ArrayType
    Dcm_DataElement_ECT_ArrayType: category=ARRAY
      element DataElement_ECT_Array: array-size=1, array-size-semantics=FIXED-SIZE, implementation-data-type=uint8
    Dcm_DataElement_RPMType: implementation-data-type=Dcm_DataElement_RPM_ArrayType
    Dcm_DataElement_RPM_ArrayType: category=ARRAY
      element DataElement_RPM_Array: array-size=2, array-size-semantics=FIXED-SIZE, implementation-data-type=uint8
    Dcm_DataElement_SystemSupplierECUHardwareVersionNumberType: implementation-data-type=Dcm_DataElement_SystemSupplierECUHardwareVersionNumber_ArrayType
    Dcm_DataElement_SystemSupplierECUHardwareVersionNumber_ArrayType: category=ARRAY
      element DataElement_SystemSupplierECUHardwareVersionNumber_Array: array-size=4, array-size-semantics=FIXED-SIZE, implementation-data-type=uint8
    Dcm_DataElement_SystemSupplierECUSoftwareNumberType: implementation-data-type=Dcm_DataElement_SystemSupplierECUSoftwareNumber_ArrayType
    Dcm_DataElement_SystemSupplierECUSoftwareNumber_ArrayType: category=ARRAY
      element DataElement_SystemSupplierECUSoftwareNumber_Array: array-size=4, array-size-semantics=FIXED-SIZE, implementation-data-type=uint8
    Dcm_DataElement_VINDataIdentifierType: implementation-data-type=Dcm_DataElement_VINDataIdentifier_ArrayType
    Dcm_DataElement_VINDataIdentifier_ArrayType: category=ARRAY
      element DataElement_VINDataIdentifier_Array: array-size=17, array-size-semantics=FIXED-SIZE, implementation-data-type=uint8
    Dcm_DataElement_VehicleManufacturerECUSoftwareVersionNumberType: implementation-data-type=Dcm_DataElement_VehicleManufacturerECUSoftwareVersionNumber_ArrayType
    Dcm_DataElement_VehicleManufacturerECUSoftwareVersionNumber_ArrayType: category=ARRAY
      element DataElement_VehicleManufacturerECUSoftwareVersionNumber_Array: array-size=17, array-size-semantics=FIXED-SIZE, implementation-data-type=uint8
    Dcm_DataElement_VehicleSpeedType: implementation-data-type=Dcm_DataElement_VehicleSpeed_ArrayType
    Dcm_DataElement_VehicleSpeed_ArrayType: category=ARRAY
      element DataElement_VehicleSpeed_Array: array-size=1, array-size-semantics=FIXED-SIZE, implementation-data-type=uint8
    Dcm_DidSupportedType: compu {0x00=DCM_DID_SUPPORTED, 0x01=DCM_DID_NOT_SUPPORTED}, range raw 0x00..0x01, implementation-data-type=uint8
    Dcm_FileAndDirNameType: category=ARRAY
      element FileAndDirName: array-size=4, array-size-semantics=FIXED-SIZE, implementation-data-type=uint8
    Dcm_IOOperationResponseType: compu {0x00=DCM_POSITIVE_RESPONSE, 0x10=DCM_GENERAL_REJECT, 0x21=DCM_BUSY_REPEAT_REQUEST, 0x22=DCM_CONDITIONS_NOT_CORRECT, 0x26=DCM_FAILURE_PREVENTS_EXECUTION, 0x31=DCM_REQUEST_OUT_OF_RANGE, 0x78=DCM_RESPONSE_PENDING}, range raw 0x00..0x78, implementation-data-type=uint8
    Dcm_InfoTypeServicesArray_VINInfoDataType: category=ARRAY
      element InfoServicesArray_VINInfoData: array-size=17, array-size-semantics=FIXED-SIZE, implementation-data-type=uint8
    Dcm_InputOutputControlParameterType: compu {0=DCM_RETURN_CONTROL_TO_ECU, 1=DCM_RESET_TO_DEFAULT, 2=DCM_FREEZE_CURRENT_STATE, 3=DCM_SHORT_TERM_ADJUSTMENT, 255=DCM_IDLE}, range raw 0..255, implementation-data-type=uint8
    Dcm_KeyArray_L9Type: category=ARRAY
      element KeyArray_L9: array-size=8, array-size-semantics=FIXED-SIZE, implementation-data-type=uint8
    Dcm_NegativeResponseCodeType:
      compu {0x00=DCM_POS_RESP, 0x10=DCM_E_GENERALREJECT, 0x11=DCM_E_SERVICENOTSUPPORTED, 0x12=DCM_E_SUBFUNCTIONNOTSUPPORTED, 0x13=DCM_E_INCORRECTMESSAGELENGTHORINVALIDFORMAT, 0x14=DCM_E_RESPONSETOOLONG, 0x21=DCM_E_BUSYREPEATREQUEST, 0x22=DCM_E_CONDITIONSNOTCORRECT, 0x24=DCM_E_REQUESTSEQUENCEERROR, 0x25=DCM_E_NORESPONSEFROMSUBNETCOMPONENT, 0x26=DCM_E_FAILUREPREVENTSEXECUTIONOFREQUESTEDACTION, 0x31=DCM_E_REQUESTOUTOFRANGE, 0x33=DCM_E_SECURITYACCESSDENIED, 0x34=DCM_E_AUTHENTICATIONREQUIRED, 0x35=DCM_E_INVALIDKEY, 0x36=DCM_E_EXCEEDNUMBEROFATTEMPTS, 0x37=DCM_E_REQUIREDTIMEDELAYNOTEXPIRED, 0x50=DCM_E_CERTIFICATEVERIFICATIONFAILEDINVALIDTIMEPERIOD, 0x51=DCM_E_CERTIFICATEVERIFICATIONFAILEDINVALIDSIGNATURE, 0x52=DCM_E_CERTIFICATEVERIFICATIONFAILEDINVALIDCHAINOFTRUST, 0x53=DCM_E_CERTIFICATEVERIFICATIONFAILEDINVALIDTYPE, 0x54=DCM_E_CERTIFICATEVERIFICATIONFAILEDINVALIDFORMAT, 0x55=DCM_E_CERTIFICATEVERIFICATIONFAILEDINVALIDCONTENT, 0x56=DCM_E_CERTIFICATEVERIFICATIONFAILEDINVALIDSCOPE, 0x57=DCM_E_CERTIFICATEVERIFICATIONFAILEDINVALIDCERTIFICATE, 0x58=DCM_E_OWNERSHIPVERIFICATIONFAILED, 0x59=DCM_E_CHALLENGECALCULATIONFAILED, 0x5A=DCM_E_SETTINGACCESSRIGHTSFAILED, 0x5B=DCM_E_SESSIONKEYCREATIONDERIVATIONFAILED, 0x5C=DCM_E_CONFIGURATIONDATAUSAGEFAILED, 0x5D=DCM_E_DEAUTHENTICATIONFAILED, 0x70=DCM_E_UPLOADDOWNLOADNOTACCEPTED, 0x71=DCM_E_TRANSFERDATASUSPENDED, 0x72=DCM_E_GENERALPROGRAMMINGFAILURE, 0x73=DCM_E_WRONGBLOCKSEQUENCECOUNTER, 0x7E=DCM_E_SUBFUNCTIONNOTSUPPORTEDINACTIVESESSION, 0x7F=DCM_E_SERVICENOTSUPPORTEDINACTIVESESSION, 0x81=DCM_E_RPMTOOHIGH, 0x82=DCM_E_RPMTOOLOW, 0x83=DCM_E_ENGINEISRUNNING, 0x84=DCM_E_ENGINEISNOTRUNNING, 0x85=DCM_E_ENGINERUNTIMETOOLOW, 0x86=DCM_E_TEMPERATURETOOHIGH, 0x87=DCM_E_TEMPERATURETOOLOW, 0x88=DCM_E_VEHICLESPEEDTOOHIGH, 0x89=DCM_E_VEHICLESPEEDTOOLOW, 0x8A=DCM_E_THROTTLE_PEDALTOOHIGH, 0x8B=DCM_E_THROTTLE_PEDALTOOLOW, 0x8C=DCM_E_TRANSMISSIONRANGENOTINNEUTRAL, 0x8D=DCM_E_TRANSMISSIONRANGENOTINGEAR, 0x8F=DCM_E_BRAKESWITCH_NOTCLOSED, 0x90=DCM_E_SHIFTERLEVERNOTINPARK, 0x91=DCM_E_TORQUECONVERTERCLUTCHLOCKED, 0x92=DCM_E_VOLTAGETOOHIGH, 0x93=DCM_E_VOLTAGETOOLOW, 0xF0=DCM_E_CRLINTEGRITYCHECKFAILED, 0xF1=DCM_E_CRLEXPIRED, 0xF2=DCM_E_ROLEANDRIGHTCERTIFICATEDENIED, 0xF3=DCM_E_SECURITYACCESSDENIEDFROMCGW, 0xF4=DCM_E_VMSCNC_4, 0xF5=DCM_E_VMSCNC_5, 0xF6=DCM_E_VMSCNC_6, 0xF7=DCM_E_VMSCNC_7, 0xF8=DCM_E_VMSCNC_8, 0xF9=DCM_E_VMSCNC_9, 0xFA=DCM_E_VMSCNC_A, 0xFB=DCM_E_VMSCNC_B, 0xFC=DCM_E_VMSCNC_C, 0xFD=DCM_E_VMSCNC_D, 0xFE=DCM_E_VMSCNC_E}
      range raw 0x00..0xFF
      implementation-data-type=uint8
    Dcm_OpStatusType: category=VALUE, base-type=uint8, compu {0=DCM_INITIAL, 1=DCM_PENDING, 2=DCM_CANCEL, 3=DCM_FORCE_RCRRP_OK}, range raw 0..3
    Dcm_ProtocolType: compu {0=DCM_OBD_ON_CAN, 1=DCM_OBD_ON_FLEXRAY, 2=DCM_OBD_ON_IP, 3=DCM_UDS_ON_CAN, 4=DCM_UDS_ON_FLEXRAY, 5=DCM_UDS_ON_IP, 6=DCM_ROE_ON_CAN, 7=DCM_ROE_ON_FLEXRAY, 8=DCM_ROE_ON_IP, 9=DCM_PERIODICTRANS_ON_CAN, 10=DCM_PERIODICTRANS_ON_FLEXRAY, 11=DCM_PERIODICTRANS_ON_IP, 12=DCM_NO_ACTIVE_PROTOCOL, 13=DCM_UDS_ON_LIN, 14=DCM_OBD_ON_UDS, 15=DCM_ZEV_ON_UDS}, range raw 0..254, implementation-data-type=uint8
    Dcm_RangeArray_DIDs_0100h_0110hType: category=ARRAY
      element RangeArray_DIDs_0100h_0110h: array-size=30, array-size-semantics=FIXED-SIZE, implementation-data-type=uint8
    Dcm_RequestControlServicesInArray_Tid1Type: category=ARRAY
      element RequestControlServicesInArray_Tid1: array-size=1, array-size-semantics=FIXED-SIZE, implementation-data-type=uint8
    Dcm_RequestControlServicesOutArray_Tid1Type: category=ARRAY
      element RequestControlServicesOutArray_Tid1: array-size=1, array-size-semantics=FIXED-SIZE, implementation-data-type=uint8
    Dcm_RequestDataArrayType: category=ARRAY
      element RequestDataArray: array-size=254, array-size-semantics=FIXED-SIZE, implementation-data-type=uint8
    Dcm_RequestDataOut_RID_0200h_CalibrationActuator_RID_0200h_RequestOutSignalType: implementation-data-type=Dcm_RequestDataOut_RID_0200h_CalibrationActuator_RID_0200h_RequestOutSignal_PrimitiveType
    Dcm_RequestDataOut_RID_0200h_CalibrationActuator_RID_0200h_RequestOutSignal_PrimitiveType: implementation-data-type=uint8
    Dcm_ResponseDataArrayType: category=ARRAY
      element ResponseDataArray: array-size=254, array-size-semantics=FIXED-SIZE, implementation-data-type=uint8
    Dcm_ScalingInfoArray_VINDataIdentifierType: category=ARRAY
      element ScalingInfoArray_VINDataIdentifier: array-size=2, array-size-semantics=FIXED-SIZE, implementation-data-type=uint8
    Dcm_ScalingInfoArray_VehicleSpeedType: category=ARRAY
      element ScalingInfoArray_VehicleSpeed: array-size=9, array-size-semantics=FIXED-SIZE, implementation-data-type=uint8
    Dcm_SecLevelType: compu {0=DCM_SEC_LEV_LOCKED, 255=DCM_SEC_LEV_ALL}, range raw 0..255, implementation-data-type=uint8
    Dcm_SeedArray_L9Type: category=ARRAY
      element SeedArray_L9: array-size=8, array-size-semantics=FIXED-SIZE, implementation-data-type=uint8
    Dcm_SesCtrlType: compu {1=DCM_DEFAULT_SESSION, 2=DCM_PROGRAMMING_SESSION, 3=DCM_EXTENDED_DIAGNOSTIC_SESSION, 4=DCM_SAFETY_SYSTEM_DIAGNOSTIC_SESSION, 5=DCM_ECU_PROGRAMMING_MODE_05H, 255=DCM_ALL_SESSION_LEVEL}, range raw 1..255, implementation-data-type=uint8
    Dcm_StartDataIn_RID_0200h_CalibrationActuator_RID_0200h_StartInSignalType: implementation-data-type=Dcm_StartDataIn_RID_0200h_CalibrationActuator_RID_0200h_StartInSignal_PrimitiveType
    Dcm_StartDataIn_RID_0200h_CalibrationActuator_RID_0200h_StartInSignal_PrimitiveType: implementation-data-type=uint8
    Dcm_StartDataOut_RID_0200h_CalibrationActuator_RID_0200h_StartOutSignalType: implementation-data-type=Dcm_StartDataOut_RID_0200h_CalibrationActuator_RID_0200h_StartOutSignal_PrimitiveType
    Dcm_StartDataOut_RID_0200h_CalibrationActuator_RID_0200h_StartOutSignal_PrimitiveType: implementation-data-type=uint8
    Dcm_StopDataIn_RID_0200h_CalibrationActuator_RID_0200h_StopInSignalType: implementation-data-type=Dcm_StopDataIn_RID_0200h_CalibrationActuator_RID_0200h_StopInSignal_PrimitiveType
    Dcm_StopDataIn_RID_0200h_CalibrationActuator_RID_0200h_StopInSignal_PrimitiveType: implementation-data-type=uint8
    Dcm_StopDataOut_RID_0200h_CalibrationActuator_RID_0200h_StopOutSignalType: implementation-data-type=Dcm_StopDataOut_RID_0200h_CalibrationActuator_RID_0200h_StopOutSignal_PrimitiveType
    Dcm_StopDataOut_RID_0200h_CalibrationActuator_RID_0200h_StopOutSignal_PrimitiveType: implementation-data-type=uint8
